# USBHOST_CM register map
Vendor: Texas Instruments
Peripheral module from a debugger description file (folder omap34xx).
Registers are 32-bit, access per field, reset 0x0 unless marked. A register's access mark holds for its fields unless they carry their own. Offsets are as the file gives them; lines under a group give offsets from that group; [hi:lo] are bit positions; {n}, {i} and the like mark numbered series; 'fields as' and 'values as' point back to an identical list; <NAME> marks a mode.

## USBHOST_CM
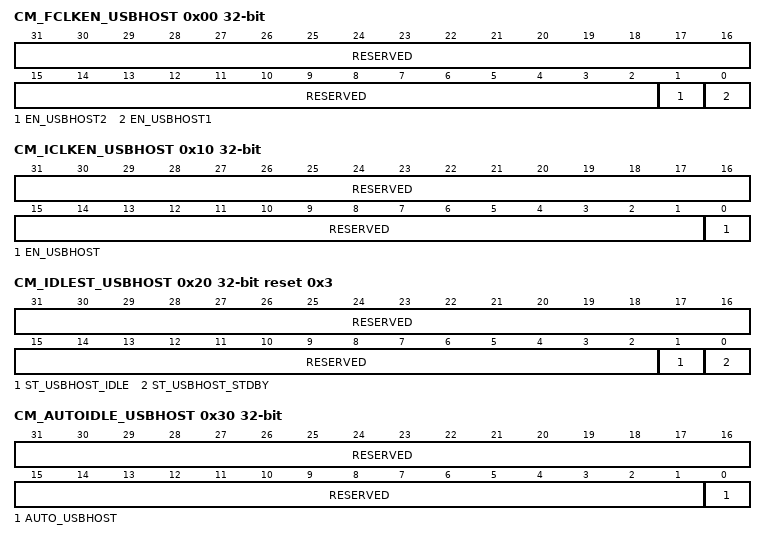
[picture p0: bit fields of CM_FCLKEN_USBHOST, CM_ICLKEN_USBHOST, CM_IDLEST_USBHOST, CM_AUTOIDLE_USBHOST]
0x00 CM_FCLKEN_USBHOST — Controls the modules functional clock activity.
  [31:2] RESERVED ro — Write 0s for future compatibility. Read returns 0.
  [1] EN_USBHOST2 rw — USB HOST 120-MHz functional clock control
    0=USBHOST_120M_FCLK is disabled; 1=USBHOST_120M_FCLK is enabled
  [0] EN_USBHOST1 rw — USB HOST 48-MHz functional clock control
    0=USBHOST_48M_FCLK is disabled; 1=USBHOST_48M_FCLK is enabled
0x10 CM_ICLKEN_USBHOST — Controls the modules interface clock activity.
  [31:1] RESERVED ro — Write 0s for future compatibility. Read returns 0.
  [0] EN_USBHOST rw — USB HOST interface clock control
    0=USB HOST interface clock is disabled; 1=USB HOST interface clock is enabled
0x20 CM_IDLEST_USBHOST ro reset 0x3 — Modules access availability monitoring. This register is read only and automatically updated.
  [31:2] RESERVED — Read returns 0.
  [1] ST_USBHOST_IDLE — USB HOST idle status.
    0=USB HOST is active; 1=USB HOST is in idle mode and cannot be accessed
  [0] ST_USBHOST_STDBY — USB HOST standby status.
    0=USB HOST is active; 1=USB HOST is in standby mode
0x30 CM_AUTOIDLE_USBHOST — This register controls the automatic control of the modules interface clock activity.
  [31:1] RESERVED ro — Write 0s for future compatibility. Read returns 0.
  [0] AUTO_USBHOST rw — USB HOST auto clock control.
    0=USB HOST interface clock is unrelated to the domain state transition; 1=USB HOST interface clock is automatically enabled or disabled along with the domain state transition
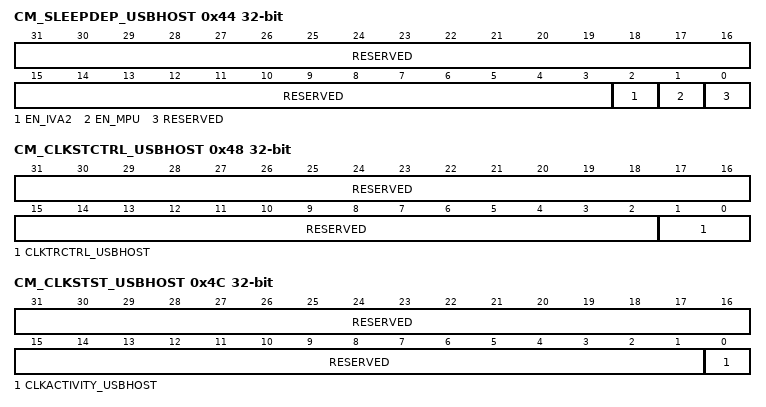
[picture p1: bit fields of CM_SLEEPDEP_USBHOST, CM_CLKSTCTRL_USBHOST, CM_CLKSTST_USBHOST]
0x44 CM_SLEEPDEP_USBHOST — This register allows enabling or disabling the sleep transition dependency of USB HOST domain with respect to other domain.
  [31:3] RESERVED ro — Write 0s for future compatibility. Read returns 0.
  [2] EN_IVA2 rw — IVA2 domain dependency
    0=USB HOST domain sleep dependency with IVA2 domain is disabled; 1=USB HOST domain sleep dependency with IVA2 domain is enabled
  [1] EN_MPU rw — MPU domain dependency
    0=USB HOST domain sleep dependency with MPU domain is disabled; 1=USB HOST domain sleep dependency with MPU domain is enabled
  [0] RESERVED ro — Write 0s for future compatibility. Read returns 0.
0x48 CM_CLKSTCTRL_USBHOST — This register enables the domain power state transition. It controls the HW supervised domain power state transition between ACTIVE and INACTIVE states.
  [31:2] RESERVED ro — Write 0s for future compatibility. Read returns 0.
  [1:0] CLKTRCTRL_USBHOST rw — Controls the clock state transition of the USB HOST clock domain.
    0=Automatic transition is disabled; 1=Start a software supervised sleep transition on the domain; 2=Start a software supervised wake-up transition on the domain; 3=Automatic transition is enabled. Transition is supervised by the HardWare.
0x4C CM_CLKSTST_USBHOST ro — This register provides a status on the interface clock activity in the domain.
  [31:1] RESERVED — Write 0s for future compatibility. Read returns 0.
  [0] CLKACTIVITY_USBHOST — Interface clock activity status
    0=No domain interface clock activity; 1=Domain interface clock is active
